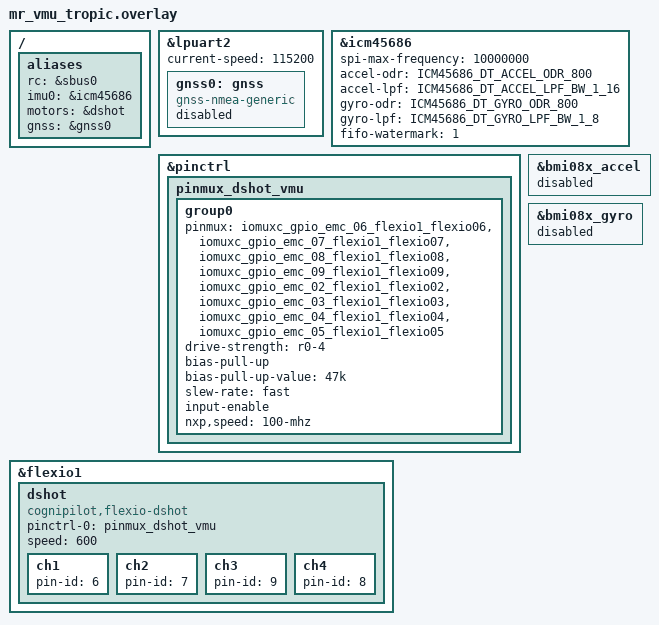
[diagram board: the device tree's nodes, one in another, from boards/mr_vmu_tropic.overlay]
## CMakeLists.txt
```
cmake_minimum_required(VERSION 3.20.0)

list(APPEND DTS_ROOT ${CMAKE_CURRENT_SOURCE_DIR})

get_filename_component(REPO_ROOT ${CMAKE_CURRENT_SOURCE_DIR} DIRECTORY)
get_filename_component(WORKSPACE_ROOT ${REPO_ROOT} DIRECTORY)
set(ZEPHYR_MODULES
  ${WORKSPACE_ROOT}/modules/hal/cmsis
  ${WORKSPACE_ROOT}/modules/hal/cmsis_6
  ${WORKSPACE_ROOT}/modules/hal/nxp
  ${WORKSPACE_ROOT}/modules/lib/cmsis-dsp
  ${WORKSPACE_ROOT}/modules/lib/zephyr_boards
)

find_package(Zephyr REQUIRED HINTS $ENV{ZEPHYR_BASE})
set(CUBS2_TARGET_NAME "cubs2_sil" CACHE STRING "CUBS2 build target/profile name")
project(${CUBS2_TARGET_NAME} LANGUAGES C)

set(CUBS2_FLATBUFFER_SCHEMA_DIR
  ${CMAKE_CURRENT_SOURCE_DIR}/src
)
set(CUBS2_FLATBUFFER_SCHEMA
  ${CUBS2_FLATBUFFER_SCHEMA_DIR}/synapse_topics.fbs
)
set(CUBS2_FLATBUFFER_MOCAP_SCHEMA
  ${CUBS2_FLATBUFFER_SCHEMA_DIR}/synapse_mocap.fbs
)
set(CUBS2_FLATBUFFER_LOG_SCHEMA
  ${CUBS2_FLATBUFFER_SCHEMA_DIR}/synapse_log.fbs
)
set(CUBS2_FLATBUFFER_SIL_SCHEMA
  ${CUBS2_FLATBUFFER_SCHEMA_DIR}/synapse_sil.fbs
)
set(CUBS2_FLATBUFFER_GENERATED_DIR
  ${CMAKE_CURRENT_BINARY_DIR}/generated/flatbuffers
)
set(CUBS2_FLATBUFFER_STAMP
  ${CUBS2_FLATBUFFER_GENERATED_DIR}/.flatcc.stamp
)
set(CUBS2_FLATBUFFER_BFBS_STAMP
  ${CUBS2_FLATBUFFER_GENERATED_DIR}/.bfbs.stamp
)
set(CUBS2_FLATBUFFER_STAGE_STAMP
  ${CUBS2_FLATBUFFER_GENERATED_DIR}/.schema-copy.stamp
)
option(CUBS2_FLATBUFFER_CODEGEN
  "Generate FlatBuffer C headers and binary schemas into the build tree when flatcc is available"
  ON
)

find_program(CUBS2_FLATCC_EXECUTABLE NAMES flatcc)

if(CUBS2_FLATCC_EXECUTABLE)
  get_filename_component(CUBS2_FLATCC_REALPATH ${CUBS2_FLATCC_EXECUTABLE} REALPATH)
  get_filename_component(CUBS2_FLATCC_BIN_DIR ${CUBS2_FLATCC_REALPATH} DIRECTORY)
  get_filename_component(CUBS2_FLATCC_PREFIX ${CUBS2_FLATCC_BIN_DIR} DIRECTORY)
endif()

find_path(CUBS2_FLATCC_INCLUDE_DIR
  NAMES flatcc/flatcc_builder.h
  HINTS ${CUBS2_FLATCC_PREFIX}/include
)

if(NOT EXISTS ${CUBS2_FLATBUFFER_SCHEMA})
  message(FATAL_ERROR
    "Missing FlatBuffer topic schema: ${CUBS2_FLATBUFFER_SCHEMA}. "
    "Run west update to fetch modules/lib/synapse_msgs_fbs."
  )
endif()

if(NOT EXISTS ${CUBS2_FLATBUFFER_MOCAP_SCHEMA})
  message(FATAL_ERROR
    "Missing FlatBuffer mocap schema: ${CUBS2_FLATBUFFER_MOCAP_SCHEMA}. "
    "Run west update to fetch modules/lib/synapse_msgs_fbs."
  )
endif()

if(NOT EXISTS ${CUBS2_FLATBUFFER_LOG_SCHEMA})
  message(FATAL_ERROR
    "Missing FlatBuffer log schema: ${CUBS2_FLATBUFFER_LOG_SCHEMA}. "
    "Run west update to fetch modules/lib/synapse_msgs_fbs."
  )
endif()

if(NOT EXISTS ${CUBS2_FLATBUFFER_SIL_SCHEMA})
  message(FATAL_ERROR
    "Missing FlatBuffer SITL schema: ${CUBS2_FLATBUFFER_SIL_SCHEMA}. "
    "Run west update to fetch modules/lib/synapse_msgs_fbs."
  )
endif()

if(CUBS2_FLATBUFFER_CODEGEN AND CUBS2_FLATCC_EXECUTABLE)
  add_custom_command(
    OUTPUT ${CUBS2_FLATBUFFER_STAGE_STAMP}
    COMMAND ${CMAKE_COMMAND} -E make_directory ${CUBS2_FLATBUFFER_GENERATED_DIR}
    COMMAND ${CMAKE_COMMAND} -E copy_if_different
            ${CUBS2_FLATBUFFER_SCHEMA}
            ${CUBS2_FLATBUFFER_GENERATED_DIR}/synapse_topics.fbs
    COMMAND ${CMAKE_COMMAND} -E copy_if_different
            ${CUBS2_FLATBUFFER_MOCAP_SCHEMA}
            ${CUBS2_FLATBUFFER_GENERATED_DIR}/synapse_mocap.fbs
    COMMAND ${CMAKE_COMMAND} -E copy_if_different
            ${CUBS2_FLATBUFFER_LOG_SCHEMA}
            ${CUBS2_FLATBUFFER_GENERATED_DIR}/synapse_log.fbs
    COMMAND ${CMAKE_COMMAND} -E copy_if_different
            ${CUBS2_FLATBUFFER_SIL_SCHEMA}
            ${CUBS2_FLATBUFFER_GENERATED_DIR}/synapse_sil.fbs
    COMMAND ${CMAKE_COMMAND} -E touch ${CUBS2_FLATBUFFER_STAGE_STAMP}
    DEPENDS
      ${CUBS2_FLATBUFFER_SCHEMA}
      ${CUBS2_FLATBUFFER_MOCAP_SCHEMA}
      ${CUBS2_FLATBUFFER_LOG_SCHEMA}
      ${CUBS2_FLATBUFFER_SIL_SCHEMA}
    COMMENT "Staging FlatBuffer schemas into ${CUBS2_FLATBUFFER_GENERATED_DIR}"
    VERBATIM
  )

  add_custom_command(
    OUTPUT ${CUBS2_FLATBUFFER_STAMP}
    COMMAND ${CUBS2_FLATCC_EXECUTABLE}
            -a
            -I${CUBS2_FLATBUFFER_SCHEMA_DIR}
            -o${CUBS2_FLATBUFFER_GENERATED_DIR}
            ${CUBS2_FLATBUFFER_SCHEMA}
    COMMAND ${CUBS2_FLATCC_EXECUTABLE}
            -a
            -I${CUBS2_FLATBUFFER_SCHEMA_DIR}
            -o${CUBS2_FLATBUFFER_GENERATED_DIR}
            ${CUBS2_FLATBUFFER_MOCAP_SCHEMA}
    COMMAND ${CUBS2_FLATCC_EXECUTABLE}
            -a
            -I${CUBS2_FLATBUFFER_SCHEMA_DIR}
            -o${CUBS2_FLATBUFFER_GENERATED_DIR}
            ${CUBS2_FLATBUFFER_LOG_SCHEMA}
    COMMAND ${CUBS2_FLATCC_EXECUTABLE}
            -a
            -I${CUBS2_FLATBUFFER_SCHEMA_DIR}
            -o${CUBS2_FLATBUFFER_GENERATED_DIR}
            ${CUBS2_FLATBUFFER_SIL_SCHEMA}
    COMMAND ${CMAKE_COMMAND} -E touch ${CUBS2_FLATBUFFER_STAMP}
    DEPENDS
      ${CUBS2_FLATBUFFER_STAGE_STAMP}
      ${CUBS2_FLATBUFFER_SCHEMA}
      ${CUBS2_FLATBUFFER_MOCAP_SCHEMA}
      ${CUBS2_FLATBUFFER_LOG_SCHEMA}
      ${CUBS2_FLATBUFFER_SIL_SCHEMA}
    COMMENT "Generating FlatBuffer headers into ${CUBS2_FLATBUFFER_GENERATED_DIR}"
    VERBATIM
  )

  add_custom_target(cubs2_flatbuffer_codegen DEPENDS ${CUBS2_FLATBUFFER_STAMP})
  add_custom_command(
    OUTPUT ${CUBS2_FLATBUFFER_BFBS_STAMP}
    COMMAND ${CUBS2_FLATCC_EXECUTABLE}
            --schema
            -I${CUBS2_FLATBUFFER_SCHEMA_DIR}
            -o${CUBS2_FLATBUFFER_GENERATED_DIR}
            ${CUBS2_FLATBUFFER_SCHEMA}
    COMMAND ${CUBS2_FLATCC_EXECUTABLE}
            --schema
            -I${CUBS2_FLATBUFFER_SCHEMA_DIR}
            -o${CUBS2_FLATBUFFER_GENERATED_DIR}
            ${CUBS2_FLATBUFFER_MOCAP_SCHEMA}
    COMMAND ${CUBS2_FLATCC_EXECUTABLE}
            --schema
            -I${CUBS2_FLATBUFFER_SCHEMA_DIR}
            -o${CUBS2_FLATBUFFER_GENERATED_DIR}
            ${CUBS2_FLATBUFFER_LOG_SCHEMA}
    COMMAND ${CUBS2_FLATCC_EXECUTABLE}
            --schema
            -I${CUBS2_FLATBUFFER_SCHEMA_DIR}
            -o${CUBS2_FLATBUFFER_GENERATED_DIR}
            ${CUBS2_FLATBUFFER_SIL_SCHEMA}
    COMMAND ${CMAKE_COMMAND} -E touch ${CUBS2_FLATBUFFER_BFBS_STAMP}
    DEPENDS
      ${CUBS2_FLATBUFFER_STAGE_STAMP}
      ${CUBS2_FLATBUFFER_SCHEMA}
      ${CUBS2_FLATBUFFER_MOCAP_SCHEMA}
      ${CUBS2_FLATBUFFER_LOG_SCHEMA}
      ${CUBS2_FLATBUFFER_SIL_SCHEMA}
    COMMENT "Generating FlatBuffer binary schemas into ${CUBS2_FLATBUFFER_GENERATED_DIR}"
    VERBATIM
  )

  add_custom_target(cubs2_flatbuffer_schema_codegen
    DEPENDS ${CUBS2_FLATBUFFER_BFBS_STAMP}
  )
elseif(CUBS2_FLATBUFFER_CODEGEN)
  message(FATAL_ERROR
    "flatcc is required to build CUBS2 because the firmware now compiles "
    "against generated FlatBuffer headers."
  )
endif()

if(NOT CUBS2_FLATCC_INCLUDE_DIR)
  message(FATAL_ERROR
    "Missing flatcc headers. Expected flatcc/flatcc_builder.h near ${CUBS2_FLATCC_EXECUTABLE}."
  )
endif()

if(TARGET cubs2_flatbuffer_codegen)
  add_dependencies(app cubs2_flatbuffer_codegen)
endif()

if(TARGET cubs2_flatbuffer_schema_codegen)
  add_dependencies(app cubs2_flatbuffer_schema_codegen)
endif()

target_include_directories(app PRIVATE
  include
  ${CUBS2_FLATBUFFER_GENERATED_DIR}
  ${CUBS2_FLATCC_INCLUDE_DIR}
  ${ZEPHYR_BASE}/../modules/hal/nxp/mcux/mcux-sdk-ng/drivers/flexio
)

add_subdirectory(src)
add_subdirectory(subsys)
add_subdirectory(drivers)
```

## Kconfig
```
source "Kconfig.zephyr"

menu "CUBS2"

choice CUBS2_SERIAL_BRIDGE_OUTPUT_PROTOCOL
	prompt "Serial bridge RC output protocol"
	default CUBS2_SERIAL_BRIDGE_INTERNAL
	help
	  Select the wire format used when publishing controller RC output over
	  the serial bridge.

config CUBS2_SERIAL_BRIDGE_INTERNAL
	bool "Internal CUBS2 bridge frame"
	help
	  Send 0x55 0xAA framed RcChannels16 payloads. This is the historical
	  SIL/bridge protocol and is not consumed by the PPM Arduino encoder.

config CUBS2_SERIAL_BRIDGE_PPM_ARDUINO
	bool "Arduino PPM encoder frame"
	help
	  Send the 14-byte packet consumed by the wsribunma/ppm_bridge Arduino:
	  0xFF 0xFF, five little-endian uint16 PWM channels, and a little-endian
	  uint16 sum checksum.

endchoice

config CUBS2_PPM_MANUAL_OVERRIDE
	bool "Select manual or autonomous PPM output from incoming RC switch"
	default y if CUBS2_SERIAL_BRIDGE_PPM_ARDUINO
	help
	  Mirror the legacy ROS ppm_bridge behavior: keep both the incoming
	  manual RC channels and the generated autonomous channels, then send
	  manual channels when the mode switch is low and autonomous channels
	  when the mode switch is high. If the manual channels or switch do not
	  look like valid PWM values, the controller stays on autonomous output.

config CUBS2_PPM_AUTO_SWITCH_CHANNEL
	int "Incoming RC channel index used for manual/autonomous switch"
	depends on CUBS2_PPM_MANUAL_OVERRIDE
	default 5
	range 0 15
	help
	  Zero-based RcChannels16 index used as the source mode switch. The
	  legacy Taranis path used joy axes[5], so channel index 5 is the
	  default equivalent.

config CUBS2_PPM_AUTO_SWITCH_THRESHOLD_US
	int "Manual/autonomous switch PWM threshold"
	depends on CUBS2_PPM_MANUAL_OVERRIDE
	default 1500
	range 1000 2000
	help
	  Switch values above this threshold select autonomous output. Values at
	  or below this threshold select manual passthrough.

config CUBS2_SERIAL_BRIDGE_CSYN_OUTPUT
	bool "Route controller output through csyn instead of serial"
	depends on CUBS2_CSYN
	default y
	help
	  Treat synapse/control_output as the Arduino-facing controller output.
	  When enabled, the legacy serial bridge send path does not write the
	  selected RC output to UART or a host serial device.

config CUBS2_SERIAL_BRIDGE_QUIET
	bool "Suppress serial bridge runtime logs"
	default y if CUBS2_SERIAL_BRIDGE_CSYN_OUTPUT
	help
	  Suppress Arduino/serial bridge runtime logs. This keeps native_sim
	  control deployments focused on csyn and controller logs while leaving
	  the legacy serial bridge code available when explicitly enabled.

config CUBS2_FWDBG_LOG
	bool "Print fixed-wing controller debug trace"
	default n
	help
	  Print the periodic FWDBG controller trace from the main control loop.
	  Enable this only when tuning or collecting controller diagnostics.

config CUBS2_HOST_DEPLOY_IO
	bool "Enable native host deploy input state"
	depends on BOARD_NATIVE_SIM
	help
	  Enable native_sim deploy input state fed by csyn topics such as
	  synapse/manual_control and synapse/mocap/frame. The selected
	  controller output is then published on synapse/control_output for an
	  external actuator or Arduino PPM node.

config CUBS2_HOST_DEPLOY_JOYSTICK
	bool "Read manual RC from Linux joystick device in zephyr.exe"
	depends on CUBS2_HOST_DEPLOY_IO
	default y
	help
	  Start a background thread inside zephyr.exe that reads /dev/input/js*
	  events and maps them into RcChannels16 for manual override selection.
	  Deployment normally leaves this disabled and feeds manual_control from
	  an external joystick node over csyn.

config CUBS2_JOYSTICK_DEVICE
	string "Linux joystick device"
	depends on CUBS2_HOST_DEPLOY_JOYSTICK
	default "/dev/input/js0"

config CUBS2_JOYSTICK_AILERON_AXIS
	int "Joystick aileron axis"
	depends on CUBS2_HOST_DEPLOY_JOYSTICK
	default 0

config CUBS2_JOYSTICK_ELEVATOR_AXIS
	int "Joystick elevator axis"
	depends on CUBS2_HOST_DEPLOY_JOYSTICK
	default 1

config CUBS2_JOYSTICK_THROTTLE_AXIS
	int "Joystick throttle axis"
	depends on CUBS2_HOST_DEPLOY_JOYSTICK
	default 2

config CUBS2_JOYSTICK_RUDDER_AXIS
	int "Joystick rudder axis"
	depends on CUBS2_HOST_DEPLOY_JOYSTICK
	default 3

config CUBS2_JOYSTICK_AUTO_BUTTON
	int "Joystick autopilot button"
	depends on CUBS2_HOST_DEPLOY_JOYSTICK
	default 0
	help
	  Button index mapped to RcChannels16 ch5. Released selects manual
	  output; pressed selects autopilot output.

rsource "subsys/Kconfig"
rsource "drivers/Kconfig"

endmenu
```

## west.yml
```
# SPDX-License-Identifier: Apache-2.0

manifest:
  self:
    path: cerebri/cubs2

  remotes:
    - name: zephyrproject-rtos
      url-base: https://github.com/zephyrproject-rtos
    - name: cognipilot
      url-base: https://github.com/CogniPilot

  projects:
    - name: zephyr
      remote: cognipilot
      revision: 2ca24fe101319435b88aa0381e9ff5f78c88a1c3
      path: zephyr
      west-commands: scripts/west-commands.yml
    - name: cmsis
      remote: zephyrproject-rtos
      revision: 512cc7e895e8491696b61f7ba8066b4a182569b8 # loaded in ~/cognipilot/ws/modules/hal/cmsis
      path: modules/hal/cmsis
    - name: cmsis-dsp
      remote: zephyrproject-rtos
      revision: 97512610ec92058f0119450b9e743eeb7e95b5c8 # loaded in ~/cognipilot/ws/modules/lib/cmsis-dsp
      path: modules/lib/cmsis-dsp
    - name: cmsis_6
      remote: zephyrproject-rtos
      revision: 30a859f44ef8ab4dc8f84b03ed586fd16ccf9d74 # loaded in ~/cognipilot/ws/modules/hal/cmsis_6
      path: modules/hal/cmsis_6
    - name: hal_nxp
      remote: cognipilot
      revision: cf8f1631e862528ee044850bcc70273975b90771 # loaded in ~/cognipilot/ws/modules/hal/nxp
      path: modules/hal/nxp
    - name: zephyr_boards
      remote: cognipilot
      revision: eed56ecf0b667552d9d82aa46d1123317f0ef36d
      path: modules/lib/zephyr_boards
    - name: synapse_msgs_fbs
      url: https://github.com/CogniPilot/synapse_msgs_fbs.git
      revision: cerebri2
      path: modules/lib/synapse_msgs_fbs
```

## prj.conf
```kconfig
CONFIG_MAIN_STACK_SIZE=6144
CONFIG_MAIN_THREAD_PRIORITY=2
CONFIG_SYSTEM_WORKQUEUE_STACK_SIZE=2048
CONFIG_THREAD_NAME=y

CONFIG_ASSERT=y
CONFIG_FPU=y

CONFIG_CUBS2_SITL_RX_PORT=4245

CONFIG_LOG=y
CONFIG_LOG_MODE_IMMEDIATE=y
CONFIG_LOG_DEFAULT_LEVEL=2
CONFIG_LOG_CMDS=y
CONFIG_LOG_BACKEND_UART=n
CONFIG_LOG_PRINTK=n

CONFIG_CONSOLE=y
CONFIG_SERIAL=y
CONFIG_UART_ASYNC_API=y
CONFIG_UART_INTERRUPT_DRIVEN=y

CONFIG_SHELL=y
CONFIG_SHELL_BACKEND_SERIAL=y
CONFIG_SHELL_LOG_BACKEND=y
CONFIG_SHELL_PROMPT_UART="cubs2:~$ "
CONFIG_SHELL_STACK_SIZE=4096
CONFIG_DEVICE_SHELL=y
CONFIG_KERNEL_SHELL=y
```

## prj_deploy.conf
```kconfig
# SPDX-License-Identifier: Apache-2.0
#
# CUBS2 deployment profile.
#
# native_sim deployment controller:
#   Zenoh/csyn mocap + manual_control -> controller -> Zenoh/csyn control_output.
# Joystick input and Arduino PPM output are separate Zenoh nodes.

CONFIG_CUBS2_SITL=n
CONFIG_CUBS2_HOST_DEPLOY_IO=y
CONFIG_CUBS2_HOST_DEPLOY_JOYSTICK=n
CONFIG_CUBS2_SERIAL_BRIDGE_INTERNAL=y
CONFIG_CUBS2_SERIAL_BRIDGE_CSYN_OUTPUT=y
CONFIG_CUBS2_PPM_MANUAL_OVERRIDE=y
```

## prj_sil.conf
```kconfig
# SPDX-License-Identifier: Apache-2.0
#
# CUBS2 software-in-the-loop profile.

CONFIG_CUBS2_SITL=y
CONFIG_CUBS2_SERIAL_BRIDGE_INTERNAL=y
```

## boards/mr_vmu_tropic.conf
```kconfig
CONFIG_INPUT=y
CONFIG_INPUT_MODE_SYNCHRONOUS=y
CONFIG_INPUT_SHELL=y
CONFIG_INPUT_EVENT_DUMP=y
CONFIG_INPUT_CRSF=y
CONFIG_INPUT_CRSF_SEND_SYNC=y
CONFIG_INPUT_CRSF_REPORT_FILTER=1
CONFIG_INPUT_CRSF_THREAD_PRIORITY=1
CONFIG_INPUT_CRSF_THREAD_STACK_SIZE=2048
CONFIG_INPUT_CRSF_USE_DTCM_FOR_DMA_BUFFER=y
CONFIG_CODE_DATA_RELOCATION=y

CONFIG_DSP=y
CONFIG_DSP_BACKEND_CMSIS=y
CONFIG_CMSIS_DSP=y

CONFIG_SENSOR=y
CONFIG_SENSOR_ASYNC_API=y
CONFIG_SENSOR_SHELL=y
CONFIG_ICM45686_STREAM=y
CONFIG_PINCTRL=y
CONFIG_CLOCK_CONTROL=y
CONFIG_DMA=y
CONFIG_SPI_NXP_LPSPI_DMA=n
CONFIG_GNSS=y
```

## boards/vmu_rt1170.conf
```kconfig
CONFIG_INPUT=y
CONFIG_INPUT_MODE_SYNCHRONOUS=y
CONFIG_INPUT_SHELL=y
CONFIG_INPUT_EVENT_DUMP=y
CONFIG_INPUT_SBUS=y
CONFIG_INPUT_SBUS_SEND_SYNC=y
CONFIG_INPUT_SBUS_REPORT_FILTER=1
CONFIG_INPUT_SBUS_THREAD_PRIORITY=1
CONFIG_INPUT_SBUS_THREAD_STACK_SIZE=2048

CONFIG_DSP=y
CONFIG_DSP_BACKEND_CMSIS=y
CONFIG_CMSIS_DSP=y

CONFIG_SENSOR=y
CONFIG_SENSOR_SHELL=y
CONFIG_ICM4268X=y
CONFIG_PINCTRL=y
CONFIG_CLOCK_CONTROL=y
CONFIG_DMA=y
CONFIG_SPI_NXP_LPSPI_DMA=n
CONFIG_GNSS=y
```

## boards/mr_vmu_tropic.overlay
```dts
/* SPDX-License-Identifier: Apache-2.0 */

#include <zephyr/dt-bindings/sensor/icm45686.h>

/ {
	aliases {
		rc = &sbus0;
		imu0 = &icm45686;
		motors = &dshot;
		gnss = &gnss0;
	};
};

&lpuart2 {
	status = "okay";
	current-speed = <115200>;

	gnss0: gnss {
		status = "disabled";
		compatible = "gnss-nmea-generic";
	};
};

&icm45686 {
	spi-max-frequency = <10000000>;
	/*
	 * Pace the flight loop directly from the IMU FIFO watermark at 800 Hz.
	 * Keep the filter settings conservative enough to cut motor vibration,
	 * but leave the SPI DMA channels intact so the FIFO read can stay off
	 * the CPU hot path.
	 */
	accel-odr = <ICM45686_DT_ACCEL_ODR_800>;
	accel-lpf = <ICM45686_DT_ACCEL_LPF_BW_1_16>;
	gyro-odr = <ICM45686_DT_GYRO_ODR_800>;
	gyro-lpf = <ICM45686_DT_GYRO_LPF_BW_1_8>;
	fifo-watermark = <1>;
};

&pinctrl {
	pinmux_dshot_vmu: pinmux_dshot_vmu {
		group0 {
			pinmux = <&iomuxc_gpio_emc_06_flexio1_flexio06>,
				 <&iomuxc_gpio_emc_07_flexio1_flexio07>,
				 <&iomuxc_gpio_emc_08_flexio1_flexio08>,
				 <&iomuxc_gpio_emc_09_flexio1_flexio09>,
				 <&iomuxc_gpio_emc_02_flexio1_flexio02>,
				 <&iomuxc_gpio_emc_03_flexio1_flexio03>,
				 <&iomuxc_gpio_emc_04_flexio1_flexio04>,
				 <&iomuxc_gpio_emc_05_flexio1_flexio05>;
			drive-strength = "r0-4";
			bias-pull-up;
			bias-pull-up-value = "47k";
			slew-rate = "fast";
			input-enable;
			nxp,speed = "100-mhz";
		};
	};
};

&flexio1 {
	status = "okay";

	dshot: dshot {
		compatible = "cognipilot,flexio-dshot";
		pinctrl-0 = <&pinmux_dshot_vmu>;
		pinctrl-names = "default";
		status = "okay";
		speed = <600>;

		ch1 {
			pin-id = <6>;
		};

		ch2 {
			pin-id = <7>;
		};

		ch3 {
			pin-id = <9>;
		};

		ch4 {
			pin-id = <8>;
		};
	};
};

&bmi08x_accel {
	status = "disabled";
};

&bmi08x_gyro {
	status = "disabled";
};
```

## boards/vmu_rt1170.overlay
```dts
/* SPDX-License-Identifier: Apache-2.0 */

/ {
	chosen {
		zephyr,console = &lpuart4;
		zephyr,shell-uart = &lpuart4;
		zephyr,uart-mcumgr = &lpuart4;
	};

	aliases {
		rc = &sbus0;
		imu0 = &icm42686_0;
		motors = &dshot;
		gnss = &gnss0;
	};
};

&lpuart2 {
	status = "okay";
	current-speed = <115200>;

	gnss0: gnss {
		status = "disabled";
		compatible = "gnss-nmea-generic";
	};
};

&lpuart6 {
	sbus0: sbus {
		status = "okay";
	};
};

&pinctrl {
	pinmux_dshot_vmu: pinmux_dshot_vmu {
	};
};

&flexio1 {
	status = "okay";

	dshot: dshot {
		compatible = "cognipilot,flexio-dshot";
		pinctrl-0 = <&pinmux_dshot_vmu>;
		pinctrl-names = "default";
		status = "okay";
		speed = <600>;

		ch1 {
			pin-id = <6>;
		};

		ch2 {
			pin-id = <7>;
		};

		ch3 {
			pin-id = <9>;
		};

		ch4 {
			pin-id = <8>;
		};
	};
};
```

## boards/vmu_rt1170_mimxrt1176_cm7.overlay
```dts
#include "vmu_rt1170.overlay"
```

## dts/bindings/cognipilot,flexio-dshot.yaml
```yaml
# Copyright 2024 NXP
# SPDX-License-Identifier: Apache-2.0

description: NXP Flexio DSHOT controller.
  Each flexio timer can be used for generating one dshot pulse.
  The two DSHOT modes supported by flexio are chosen based on the selected polarity -
  Dual 8-bit counters DSHOT mode and Dual 8-bit counters DSHOT Low mode.

compatible: "cognipilot,flexio-dshot"

include: [pinctrl-device.yaml, base.yaml]

properties:
  pinctrl-0:
    required: true

  pinctrl-names:
    required: true

  speed:
    type: int
    default: 600
    description: |
      bitrate of the dshot signal in kbit/s

child-binding:
  description: |
    Flexio DSHOT channel configuration.

  properties:
    pin-id:
      type: int
      required: true
      description: |
        pin-id should be populated with number 'n' specified in the
        FXIO_D<n> data pin of your board's schematic.
    bidirectional-dshot:
      type: boolean
      description: | 
        Enables inverted dshot, where signal level is inverted
        When inverted an DSHOT esc will send back telemetry over 
        the same single wire
```

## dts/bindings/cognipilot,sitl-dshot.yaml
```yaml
# SPDX-License-Identifier: Apache-2.0

description: CUBS2 native_sim DSHOT output device

compatible: "cognipilot,sitl-dshot"

include: sensor-device.yaml

properties:
  channel-count:
    type: int
    required: true
    description: Number of simulated motor output channels.
```

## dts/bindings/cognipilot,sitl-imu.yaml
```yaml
# SPDX-License-Identifier: Apache-2.0

description: CUBS2 native_sim IMU sensor device

compatible: "cognipilot,sitl-imu"

include: sensor-device.yaml
```

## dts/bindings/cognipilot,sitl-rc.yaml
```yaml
# SPDX-License-Identifier: Apache-2.0

description: CUBS2 native_sim RC input device

compatible: "cognipilot,sitl-rc"

include: base.yaml
```

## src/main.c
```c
/*
 * SPDX-License-Identifier: Apache-2.0
 */

#include "control_io.h"
#include "hotpath_memory.h"
#include "topic_shell.h"
#include "serial_bridge.h"
#include "generated_fixed_wing/CubControl_FixedWingOuterLoop.h"

#include <stdbool.h>
#include <stdint.h>
#include <math.h>

#include <zephyr/kernel.h>
#include <zephyr/logging/log.h>

LOG_MODULE_REGISTER(cubs2, LOG_LEVEL_INF);

struct control_context {
	synapse_topic_Vec3f_t gyro;
	synapse_topic_Vec3f_t accel;
	synapse_topic_RcChannels16_t rc;
	synapse_topic_ControlStatus_t status;
	synapse_topic_AttitudeEuler_t attitude;
	synapse_topic_AttitudeEuler_t attitude_desired;
	synapse_topic_RateTriplet_t rate_desired;
	synapse_topic_RateTriplet_t rate_cmd;
	cubs2_mocap_rigid_body_t mocap;
	float dt;
	int64_t now_ms;
};

/* Keep the persistent control-loop working set in DTCM if available. */
static CUBS2_HOTPATH_DTCM_BSS CubControl_FixedWingOuterLoop_t g_model;
static CUBS2_HOTPATH_DTCM_BSS struct control_context g_control_ctx;

static void publish_bridge_state(const struct control_context *ctx)
{
	cubs2_topic_flight_state_publish(&ctx->gyro, &ctx->accel, &ctx->rc, &ctx->status,
					   &ctx->attitude, &ctx->attitude_desired,
					   &ctx->rate_desired, &ctx->rate_cmd);
}

static float clampf_local(float value, float min_value, float max_value)
{
	if (value < min_value) {
		return min_value;
	}
	if (value > max_value) {
		return max_value;
	}
	return value;
}

static int32_t pwm_from_centered_stick(float value, bool inverted)
{
	const float sign = inverted ? -1.0f : 1.0f;
	return (int32_t)(1500.0f + 500.0f * sign * clampf_local(value, -1.0f, 1.0f));
}

static int32_t pwm_from_throttle(float value)
{
	return (int32_t)(1000.0f + 1000.0f * clampf_local(value, 0.0f, 1.0f));
}

static void quat_to_euler(const cubs2_mocap_rigid_body_t *mocap, float *roll, float *pitch,
				  float *yaw)
{
	const float qw = mocap->qw;
	const float qx = mocap->qx;
	const float qy = mocap->qy;
	const float qz = mocap->qz;
	const float sinr_cosp = 2.0f * (qw * qx + qy * qz);
	const float cosr_cosp = 1.0f - 2.0f * (qx * qx + qy * qy);
	const float sinp = 2.0f * (qw * qy - qz * qx);
	const float siny_cosp = 2.0f * (qw * qz + qx * qy);
	const float cosy_cosp = 1.0f - 2.0f * (qy * qy + qz * qz);

	*roll = atan2f(sinr_cosp, cosr_cosp);
	*pitch = asinf(clampf_local(sinp, -1.0f, 1.0f));
	*yaw = atan2f(siny_cosp, cosy_cosp);
}

static void fixed_wing_bridge_map_input(CubControl_FixedWingOuterLoop_t *m, const struct control_context *ctx)
{
	float roll = ctx->accel.x;
	float pitch = ctx->accel.y;
	float yaw = ctx->accel.z;

	if (ctx->mocap.valid) {
		quat_to_euler(&ctx->mocap, &roll, &pitch, &yaw);
		pitch = -pitch;
		m->x = ctx->mocap.x;
		m->y = ctx->mocap.y;
		m->z = ctx->mocap.z;
	} else {
		m->x = ctx->gyro.x;
		m->y = ctx->gyro.y;
		m->z = ctx->gyro.z;
	}

	m->roll = roll;
	m->pitch = pitch;
	m->yaw = yaw;
}

static void fixed_wing_bridge_map_output(const CubControl_FixedWingOuterLoop_t *m, synapse_topic_RcChannels16_t *rc)
{
	rc->ch0 = pwm_from_centered_stick((float)m->aileron, true);
	rc->ch1 = pwm_from_centered_stick((float)m->elevator, true);
	rc->ch2 = pwm_from_throttle((float)m->throttle);
	rc->ch3 = pwm_from_centered_stick((float)m->rudder, false);
	rc->ch4 = (int32_t)clampf_local((float)m->stabilizer, 1000.0f, 2000.0f);
	rc->ch5 = (int32_t)m->current_wp;
	rc->ch6 = (int32_t)(1000.0f * (float)m->des_v);
	rc->ch7 = (int32_t)(1000.0f * (float)m->phi_cmd);
	rc->ch8 = (int32_t)(1000.0f * (float)m->chi_err);
}

static bool fixed_wing_bridge_auto_mode(const synapse_topic_RcChannels16_t *manual_rc,
					const synapse_topic_ControlStatus_t *status)
{
#if defined(CONFIG_CUBS2_PPM_MANUAL_OVERRIDE)
	const int32_t *manual_channels = cubs2_topic_rc_channels_data_const(manual_rc);
	bool manual_valid = status->rc_valid;
	int32_t switch_us = manual_channels[CONFIG_CUBS2_PPM_AUTO_SWITCH_CHANNEL];

	for (size_t i = 0U; i < 5U; i++) {
		manual_valid = manual_valid && (manual_channels[i] >= 900) &&
			       (manual_channels[i] <= 2100);
	}
	manual_valid = manual_valid && (switch_us >= 900) && (switch_us <= 2100);

	return !manual_valid || (switch_us > CONFIG_CUBS2_PPM_AUTO_SWITCH_THRESHOLD_US);
#else
	ARG_UNUSED(manual_rc);
	ARG_UNUSED(status);
	return true;
#endif
}

static bool fixed_wing_bridge_select_ppm_output(
	const synapse_topic_RcChannels16_t *manual_rc, const synapse_topic_RcChannels16_t *auto_rc,
	const synapse_topic_ControlStatus_t *status, bool auto_mode, synapse_topic_RcChannels16_t *out_rc)
{
#if defined(CONFIG_CUBS2_PPM_MANUAL_OVERRIDE)
	const int32_t *manual_channels = cubs2_topic_rc_channels_data_const(manual_rc);
#if !defined(CONFIG_CUBS2_SERIAL_BRIDGE_QUIET)
	static int s_last_auto_mode = -1;
#endif
	bool manual_valid = status->rc_valid;
	int32_t switch_us = manual_channels[CONFIG_CUBS2_PPM_AUTO_SWITCH_CHANNEL];

	for (size_t i = 0U; i < 5U; i++) {
		manual_valid = manual_valid && (manual_channels[i] >= 900) &&
			       (manual_channels[i] <= 2100);
	}
	manual_valid = manual_valid && (switch_us >= 900) && (switch_us <= 2100);

	*out_rc = auto_mode ? *auto_rc : *manual_rc;

#if !defined(CONFIG_CUBS2_SERIAL_BRIDGE_QUIET)
	if ((int)auto_mode != s_last_auto_mode) {
		if (manual_valid) {
			LOG_INF("PPM bridge mode: %s switch_ch%u=%ld",
				auto_mode ? "auto" : "manual",
				(unsigned int)CONFIG_CUBS2_PPM_AUTO_SWITCH_CHANNEL,
				(long)switch_us);
		} else {
			LOG_INF("PPM bridge mode: auto (manual RC unavailable)");
		}
		s_last_auto_mode = (int)auto_mode;
	}
#endif

	return auto_mode;
#else
	ARG_UNUSED(manual_rc);
	ARG_UNUSED(status);
	ARG_UNUSED(auto_mode);
	*out_rc = *auto_rc;
	return true;
#endif
}

int main(void)
{
	struct control_context *const ctx = &g_control_ctx;
	const k_timeout_t controller_timeout =
		K_NSEC(CUBCONTROL_FIXEDWINGOUTERLOOP_PERIOD_NS);
	bool previous_auto_mode = false;
	int rc;

	*ctx = (struct control_context){0};
	CubControl_FixedWingOuterLoop_init(&g_model);
	g_model.dt = CUBCONTROL_FIXEDWINGOUTERLOOP_PERIOD_S;

	rc = cubs2_control_io_init();
	if (rc != 0) {
		return rc;
	}

	rc = cubs2_serial_bridge_init();
	if (rc != 0) {
#if !defined(CONFIG_CUBS2_SERIAL_BRIDGE_QUIET)
		LOG_ERR("Failed to initialize serial bridge: %d", rc);
#endif
	}

	LOG_INF("CUBS2 Fixed-Wing Bridge starting");

	while (true) {
		// Wait for next telemetry packet or generated-period trigger. In SITL this
		// also stages the simulated mocap pose; on flight hardware it
		// leaves ctx->mocap invalid.
		cubs2_control_input_wait(&ctx->gyro, &ctx->accel, &ctx->rc, &ctx->status,
					 CUBCONTROL_FIXEDWINGOUTERLOOP_PERIOD_S,
					 controller_timeout, &ctx->dt, &ctx->mocap);
		ctx->now_ms = k_uptime_get();
		synapse_topic_RcChannels16_t manual_rc = ctx->rc;
		synapse_topic_RcChannels16_t auto_rc = {0};
		bool auto_mode = fixed_wing_bridge_auto_mode(&manual_rc, &ctx->status);

		// Fall back to the serial bridge mocap source when no other source
		// has provided a valid pose this cycle.
		if (!ctx->mocap.valid) {
			cubs2_serial_bridge_get_mocap(&ctx->mocap);
		}

		if (auto_mode && !previous_auto_mode) {
			CubControl_FixedWingOuterLoop_init(&g_model);
			g_model.dt = CUBCONTROL_FIXEDWINGOUTERLOOP_PERIOD_S;
		}
		previous_auto_mode = auto_mode;

		// Update model inputs
		fixed_wing_bridge_map_input(&g_model, ctx);

		// Advance one generated-period discrete control step.
		CubControl_FixedWingOuterLoop_step(&g_model);

		// Map model outputs to autonomous RC sticks, then mirror the legacy
		// ROS ppm_bridge manual/autonomous switch behavior.
		fixed_wing_bridge_map_output(&g_model, &auto_rc);
		(void)fixed_wing_bridge_select_ppm_output(&manual_rc, &auto_rc, &ctx->status, auto_mode,
							  &ctx->rc);

#if defined(CONFIG_CUBS2_FWDBG_LOG)
		LOG_INF("FWDBG,%.3f,%.3f,%.3f,%.3f,%.3f,%.3f,%.3f,%.3f,%.3f,%.3f,%.3f,%.3f,%.3f,%.3f,%.3f,%.3f,%d,%d,%.3f,%.3f",
			(double)g_model.time_s,
			(double)g_model.x, (double)g_model.y,
			(double)g_model.z, (double)g_model.roll,
			(double)g_model.pitch, (double)g_model.yaw,
			(double)g_model.aileron, (double)g_model.elevator,
			(double)g_model.throttle, (double)g_model.rudder,
			(double)g_model.stabilizer, (double)g_model.des_heading,
			(double)g_model.vx_est, (double)g_model.vy_est,
			(double)g_model.phi_cmd, (double)g_model.chi_err,
			(int)g_model.current_wp, (int)g_model.airborne,
			(double)g_model.des_v, (double)g_model.des_gamma);
#endif

		// Publish stick overrides to the bridge output
		publish_bridge_state(ctx);
		cubs2_topic_rc_published();

		// Send RC overrides back to Ubuntu bridge
		cubs2_serial_bridge_send_rc(&ctx->rc);
	}

	return 0;
}
```

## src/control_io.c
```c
/*
 * SPDX-License-Identifier: Apache-2.0
 */

#include "control_io.h"

#include <errno.h>

#include <zephyr/kernel.h>
#include <zephyr/logging/log.h>

#if defined(CONFIG_CUBS2_SITL)
#include "sitl_flatbuffer.h"
#include "sitl_udp_coordinator.h"
#endif

#if defined(CONFIG_CUBS2_HOST_DEPLOY_IO)
#include "host_deploy_io.h"
#endif

LOG_MODULE_DECLARE(cubs2, LOG_LEVEL_INF);

K_SEM_DEFINE(g_input_sem, 0, 1);

int cubs2_control_io_init(void)
{
#if defined(CONFIG_CUBS2_HOST_DEPLOY_IO)
	return cubs2_host_deploy_io_init();
#else
	return 0;
#endif
}

void cubs2_control_input_trigger(void)
{
	k_sem_give(&g_input_sem);
}

void cubs2_control_input_wait(synapse_topic_Vec3f_t *gyro,
				synapse_topic_Vec3f_t *accel,
				synapse_topic_RcChannels16_t *rc,
				synapse_topic_ControlStatus_t *status,
				float controller_period_s,
				k_timeout_t controller_timeout,
				float *dt,
				cubs2_mocap_rigid_body_t *mocap)
{
	uint8_t rc_link_quality = 0U;
	bool rc_valid = false;
	bool imu_valid = false;

#if !defined(CONFIG_CUBS2_SITL)
	// Flight: wait for the next input trigger or one generated controller period.
	(void)k_sem_take(&g_input_sem, controller_timeout);
#endif

	// Default values if no real sensor data is present
	*dt = controller_period_s;
	status->imu_ok = true;
	status->rc_valid = true;

	// Default: no mocap from this source (flight build gets it from the
	// serial bridge instead).
	if (mocap != NULL) {
		*mocap = (cubs2_mocap_rigid_body_t){0};
	}

#if defined(CONFIG_CUBS2_SITL)
	uint8_t buf[CUBS2_SITL_INPUT_MAX_SIZE];
	size_t len = 0U;
	uint32_t generation = 0U;
	static uint32_t s_last_generation;   // last plant step we consumed
	bool have_input = false;

	// Lockstep: block until the plant publishes a NEW input (its generation
	// counter bumps). The controller dt still comes from the generated
	// Modelica period passed above; the plant/bridge decides packet cadence. Two
	// guards keep it from deadlocking:
	//   * before any pose has arrived (generation == 0) proceed immediately, so
	//     the controller emits a first packet to prime the (also-waiting) plant;
	//   * a 1 s ceiling keeps a dead/paused peer from hanging the loop forever.
	static bool s_primed;   // emitted the initial control to prime the plant?
	const int64_t deadline = k_uptime_get() + 1000;
	while (true) {
		uint32_t gen;
		size_t l;

		if (cubs2_sitl_udp_latest_input_get(buf, sizeof(buf), &l, &gen)) {
			if (gen != s_last_generation) {
				s_last_generation = gen;
				len = l;
				have_input = true;
				s_primed = true;
				break;   // fresh plant step -> consume it
			}
		} else if (!s_primed) {
			s_primed = true;
			break;   // no pose has ever arrived -> emit one control to prime
		}
		if (k_uptime_get() >= deadline) {
			break;   // safety: peer stalled
		}
		// Yield so the SITL rx thread can drain the plant's reply. (This also
		// replaces the yield the old k_sem_take used to provide.)
		k_sleep(K_MSEC(1));
	}
	(void)generation;

	if (have_input &&
	    cubs2_sitl_fb_unpack_input(buf, len, gyro, accel, rc, &rc_link_quality, &rc_valid,
				       &imu_valid, mocap)) {
		status->rc_link_quality = rc_link_quality;
		status->rc_valid = rc_valid;
		status->imu_ok = imu_valid;
	}
#else
	ARG_UNUSED(rc_link_quality);
	ARG_UNUSED(rc_valid);
	ARG_UNUSED(imu_valid);
#endif

#if defined(CONFIG_CUBS2_HOST_DEPLOY_IO)
	if (mocap != NULL) {
		(void)cubs2_host_deploy_io_get_mocap(mocap);
	}
	if (cubs2_host_deploy_io_get_rc(rc)) {
		status->rc_valid = true;
		status->rc_link_quality = 100U;
	} else {
		status->rc_valid = false;
		status->rc_link_quality = 0U;
	}
#endif
}
```

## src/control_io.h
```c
#ifndef CUBS2_CONTROL_IO_H_
#define CUBS2_CONTROL_IO_H_

#include "topic_flatbuffer.h"

#include <zephyr/kernel.h>

int cubs2_control_io_init(void);
void cubs2_control_input_wait(synapse_topic_Vec3f_t *gyro,
				synapse_topic_Vec3f_t *accel,
				synapse_topic_RcChannels16_t *rc,
				synapse_topic_ControlStatus_t *status,
				float controller_period_s,
				k_timeout_t controller_timeout,
				float *dt,
				cubs2_mocap_rigid_body_t *mocap);

void cubs2_control_input_trigger(void);

#endif
```

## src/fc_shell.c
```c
/*
 * SPDX-License-Identifier: Apache-2.0
 */

#include "topic_shell.h"
#include "flight_mode.h"

#include <zephyr/kernel.h>
#include <zephyr/shell/shell.h>

static void fc_latest_state(synapse_topic_Vec3f_t *gyro, synapse_topic_Vec3f_t *accel,
			    synapse_topic_RcChannels16_t *rc,
			    synapse_topic_ControlStatus_t *status,
			    synapse_topic_AttitudeEuler_t *attitude,
			    synapse_topic_AttitudeEuler_t *attitude_desired,
			    synapse_topic_RateTriplet_t *rate_desired,
			    synapse_topic_RateTriplet_t *rate_cmd)
{
	(void)cubs2_topic_flight_state_get(gyro, accel, rc, status, attitude,
					     attitude_desired, rate_desired, rate_cmd);
}

static int cmd_fc_status(const struct shell *sh, size_t argc, char **argv)
{
	synapse_topic_Vec3f_t gyro = {0};
	synapse_topic_Vec3f_t accel = {0};
	synapse_topic_RcChannels16_t rc = {0};
	synapse_topic_ControlStatus_t status = {0};
	synapse_topic_AttitudeEuler_t attitude = {0};
	synapse_topic_AttitudeEuler_t attitude_desired = {0};
	synapse_topic_RateTriplet_t rate_desired = {0};
	synapse_topic_RateTriplet_t rate_cmd = {0};
	int64_t now_ms = k_uptime_get();
	int64_t rc_age_ms;

	ARG_UNUSED(argc);
	ARG_UNUSED(argv);

	fc_latest_state(&gyro, &accel, &rc, &status, &attitude, &attitude_desired,
			&rate_desired, &rate_cmd);
	rc_age_ms = status.rc_valid ? (now_ms - status.rc_stamp_ms) : -1;

	shell_print(sh,
		    "mode=%s armed=%d imu_ok=%d rc_valid=%d rc_stale=%d arm_switch=%d rc_age_ms=%lld lq=%u throttle_us=%ld",
		    cubs2_flight_mode_name((enum cubs2_flight_mode)status.flight_mode),
		    status.armed ? 1 : 0,
		    status.imu_ok ? 1 : 0,
		    status.rc_valid ? 1 : 0,
		    status.rc_stale ? 1 : 0,
		    status.arm_switch ? 1 : 0,
		    (long long)rc_age_ms,
		    (unsigned int)status.rc_link_quality,
		    (long)status.throttle_us);
	shell_print(sh,
		    "rate_desired roll=%0.3f pitch=%0.3f yaw=%0.3f rate_cmd roll=%0.3f pitch=%0.3f yaw=%0.3f",
		    (double)rate_desired.roll,
		    (double)rate_desired.pitch,
		    (double)rate_desired.yaw,
		    (double)rate_cmd.roll,
		    (double)rate_cmd.pitch,
		    (double)rate_cmd.yaw);
	shell_print(sh,
		    "attitude roll=%0.3f pitch=%0.3f yaw=%0.3f attitude_desired roll=%0.3f pitch=%0.3f yaw=%0.3f",
		    (double)attitude.roll,
		    (double)attitude.pitch,
		    (double)attitude.yaw,
		    (double)attitude_desired.roll,
		    (double)attitude_desired.pitch,
		    (double)attitude_desired.yaw);

	return 0;
}

static int cmd_fc_gyro(const struct shell *sh, size_t argc, char **argv)
{
	synapse_topic_Vec3f_t gyro = {0};
	synapse_topic_Vec3f_t accel = {0};
	synapse_topic_RcChannels16_t rc = {0};
	synapse_topic_ControlStatus_t status = {0};
	synapse_topic_AttitudeEuler_t attitude = {0};
	synapse_topic_AttitudeEuler_t attitude_desired = {0};
	synapse_topic_RateTriplet_t rate_desired = {0};
	synapse_topic_RateTriplet_t rate_cmd = {0};

	ARG_UNUSED(argc);
	ARG_UNUSED(argv);

	fc_latest_state(&gyro, &accel, &rc, &status, &attitude, &attitude_desired,
			&rate_desired, &rate_cmd);

	shell_print(sh,
		    "gyro_rad_s x=%0.5f y=%0.5f z=%0.5f",
		    (double)gyro.x,
		    (double)gyro.y,
		    (double)gyro.z);
	shell_print(sh,
		    "accel_m_s2 x=%0.5f y=%0.5f z=%0.5f",
		    (double)accel.x,
		    (double)accel.y,
		    (double)accel.z);

	return 0;
}

static int cmd_fc_rc(const struct shell *sh, size_t argc, char **argv)
{
	synapse_topic_Vec3f_t gyro = {0};
	synapse_topic_Vec3f_t accel = {0};
	synapse_topic_RcChannels16_t rc = {0};
	synapse_topic_ControlStatus_t status = {0};
	synapse_topic_AttitudeEuler_t attitude = {0};
	synapse_topic_AttitudeEuler_t attitude_desired = {0};
	synapse_topic_RateTriplet_t rate_desired = {0};
	synapse_topic_RateTriplet_t rate_cmd = {0};

	ARG_UNUSED(argc);
	ARG_UNUSED(argv);

	fc_latest_state(&gyro, &accel, &rc, &status, &attitude, &attitude_desired,
			&rate_desired, &rate_cmd);

	shell_print(sh,
		    "rc us ch0=%ld ch1=%ld ch2=%ld ch3=%ld ch4=%ld ch5=%ld ch6=%ld ch7=%ld",
		    (long)rc.ch0,
		    (long)rc.ch1,
		    (long)rc.ch2,
		    (long)rc.ch3,
		    (long)rc.ch4,
		    (long)rc.ch5,
		    (long)rc.ch6,
		    (long)rc.ch7);

	return 0;
}

SHELL_STATIC_SUBCMD_SET_CREATE(
	sub_fc,
	SHELL_CMD(status, NULL, "show latest flight-control state", cmd_fc_status),
	SHELL_CMD(gyro, NULL, "show latest gyro and accel sample", cmd_fc_gyro),
	SHELL_CMD(rc, NULL, "show latest RC channel sample", cmd_fc_rc),
	SHELL_SUBCMD_SET_END);
SHELL_CMD_REGISTER(fc, &sub_fc, "flight-control debug commands", NULL);
```

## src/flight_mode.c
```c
/*
 * SPDX-License-Identifier: Apache-2.0
 */

#include "flight_mode.h"

enum cubs2_flight_mode cubs2_flight_mode_from_rc(
	const synapse_topic_RcChannels16_t *rc)
{
	const int32_t *channels;

	if (rc == NULL) {
		return CUBS2_FLIGHT_MODE_ACRO;
	}

	channels = cubs2_topic_rc_channels_data_const(rc);
	if (channels[CUBS2_FLIGHT_MODE_CHANNEL_INDEX] >= CUBS2_FLIGHT_MODE_SWITCH_US) {
		return CUBS2_FLIGHT_MODE_AUTO_LEVEL;
	}

	return CUBS2_FLIGHT_MODE_ACRO;
}

const char *cubs2_flight_mode_name(enum cubs2_flight_mode mode)
{
	switch (mode) {
	case CUBS2_FLIGHT_MODE_ACRO:
		return "ACRO";
	case CUBS2_FLIGHT_MODE_AUTO_LEVEL:
		return "AUTO_LEVEL";
	default:
		return "UNKNOWN";
	}
}
```

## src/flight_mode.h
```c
/*
 * SPDX-License-Identifier: Apache-2.0
 */

#ifndef CUBS2_FLIGHT_MODE_H_
#define CUBS2_FLIGHT_MODE_H_

enum cubs2_flight_mode {
	CUBS2_FLIGHT_MODE_UNKNOWN = 0,
	CUBS2_FLIGHT_MODE_ACRO = 1,
	CUBS2_FLIGHT_MODE_AUTO_LEVEL = 2,
};

#endif /* CUBS2_FLIGHT_MODE_H_ */
```

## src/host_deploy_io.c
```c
/*
 * SPDX-License-Identifier: Apache-2.0
 */

#include "host_deploy_io.h"
#include "control_io.h"

#include <errno.h>
#include <string.h>

#include <zephyr/kernel.h>
#include <zephyr/logging/log.h>

#if defined(CONFIG_CUBS2_HOST_DEPLOY_JOYSTICK)
#include <fcntl.h>
#include <linux/joystick.h>
#include <unistd.h>
#endif

LOG_MODULE_REGISTER(cubs2_host_deploy_io, LOG_LEVEL_INF);

#define HOST_DEPLOY_JOYSTICK_STACK_SIZE 2048
#define HOST_DEPLOY_JOYSTICK_PRIORITY 5

static struct k_mutex g_input_mutex;
static cubs2_mocap_rigid_body_t g_latest_mocap;
static synapse_topic_RcChannels16_t g_latest_rc;
static bool g_have_mocap;
static bool g_have_rc;

#if defined(CONFIG_CUBS2_HOST_DEPLOY_JOYSTICK)
K_THREAD_STACK_DEFINE(g_joystick_stack, HOST_DEPLOY_JOYSTICK_STACK_SIZE);
static struct k_thread g_joystick_thread;
#endif

void cubs2_host_deploy_io_put_rc(const synapse_topic_RcChannels16_t *rc, bool valid)
{
	if (rc == NULL) {
		return;
	}

	k_mutex_lock(&g_input_mutex, K_FOREVER);
	g_latest_rc = *rc;
	g_have_rc = valid;
	k_mutex_unlock(&g_input_mutex);

	if (valid) {
		cubs2_control_input_trigger();
	}
}

void cubs2_host_deploy_io_put_mocap_payload(const uint8_t *buf, size_t len)
{
	cubs2_mocap_rigid_body_t mocap;
	const float mocap_mm_to_m = 0.001f;

	if (buf == NULL || !cubs2_topic_fb_unpack_mocap_frame(buf, len, &mocap)) {
		return;
	}

	mocap.x *= mocap_mm_to_m;
	mocap.y *= mocap_mm_to_m;
	mocap.z *= mocap_mm_to_m;

	k_mutex_lock(&g_input_mutex, K_FOREVER);
	g_latest_mocap = mocap;
	g_have_mocap = mocap.valid;
	k_mutex_unlock(&g_input_mutex);

	cubs2_control_input_trigger();
}

bool cubs2_host_deploy_io_get_mocap(cubs2_mocap_rigid_body_t *mocap)
{
	bool have_mocap;

	if (mocap == NULL) {
		return false;
	}

	k_mutex_lock(&g_input_mutex, K_FOREVER);
	*mocap = g_latest_mocap;
	have_mocap = g_have_mocap;
	k_mutex_unlock(&g_input_mutex);

	return have_mocap;
}

bool cubs2_host_deploy_io_get_rc(synapse_topic_RcChannels16_t *rc)
{
	bool have_rc;

	if (rc == NULL) {
		return false;
	}

	k_mutex_lock(&g_input_mutex, K_FOREVER);
	*rc = g_latest_rc;
	have_rc = g_have_rc;
	k_mutex_unlock(&g_input_mutex);

	return have_rc;
}

#if defined(CONFIG_CUBS2_HOST_DEPLOY_JOYSTICK)
static void host_deploy_store_rc(const synapse_topic_RcChannels16_t *rc)
{
	k_mutex_lock(&g_input_mutex, K_FOREVER);
	g_latest_rc = *rc;
	g_have_rc = true;
	k_mutex_unlock(&g_input_mutex);
}

static int32_t joystick_axis_to_pwm(int16_t value, bool inverted)
{
	int32_t centered = 1500;
	int32_t scaled = ((int32_t)value * 500) / 32767;

	if (inverted) {
		scaled = -scaled;
	}

	return centered + scaled;
}

static int32_t joystick_throttle_to_pwm(int16_t value)
{
	/* Linux joystick axes are usually -32767..32767. Map high stick to 2000. */
	return 1000 + (((int32_t)(32767 - value) * 1000) / 65534);
}

static void joystick_apply_axis(synapse_topic_RcChannels16_t *rc, uint8_t axis, int16_t value)
{
	switch (axis) {
	case CONFIG_CUBS2_JOYSTICK_AILERON_AXIS:
		rc->ch0 = joystick_axis_to_pwm(value, false);
		break;
	case CONFIG_CUBS2_JOYSTICK_ELEVATOR_AXIS:
		rc->ch1 = joystick_axis_to_pwm(value, true);
		break;
	case CONFIG_CUBS2_JOYSTICK_THROTTLE_AXIS:
		rc->ch2 = joystick_throttle_to_pwm(value);
		break;
	case CONFIG_CUBS2_JOYSTICK_RUDDER_AXIS:
		rc->ch3 = joystick_axis_to_pwm(value, false);
		break;
	default:
		break;
	}
}

static void joystick_apply_button(synapse_topic_RcChannels16_t *rc, uint8_t button, int16_t value)
{
	if (button == CONFIG_CUBS2_JOYSTICK_AUTO_BUTTON) {
		rc->ch5 = value ? 2000 : 1000;
	}
}

static void joystick_thread(void *p1, void *p2, void *p3)
{
	ARG_UNUSED(p1);
	ARG_UNUSED(p2);
	ARG_UNUSED(p3);

	while (true) {
		const char *device = CONFIG_CUBS2_JOYSTICK_DEVICE;
		int fd = open(device, O_RDONLY);

		if (fd < 0) {
			LOG_WRN("joystick open failed for %s: %d", device, errno);
			k_sleep(K_SECONDS(1));
			continue;
		}

		LOG_INF("joystick opened on %s", device);

		synapse_topic_RcChannels16_t rc = {
			.ch0 = 1500,
			.ch1 = 1500,
			.ch2 = 1000,
			.ch3 = 1500,
			.ch4 = 1900,
			.ch5 = 1000,
		};

		host_deploy_store_rc(&rc);

		while (true) {
			struct js_event event;
			ssize_t n = read(fd, &event, sizeof(event));

			if (n != sizeof(event)) {
				LOG_WRN("joystick read failed for %s: %d", device, errno);
				break;
			}

			event.type &= ~JS_EVENT_INIT;
			if (event.type == JS_EVENT_AXIS) {
				joystick_apply_axis(&rc, event.number, event.value);
				host_deploy_store_rc(&rc);
			} else if (event.type == JS_EVENT_BUTTON) {
				joystick_apply_button(&rc, event.number, event.value);
				host_deploy_store_rc(&rc);
			}
		}

		close(fd);
		k_sleep(K_MSEC(250));
	}
}
#endif

int cubs2_host_deploy_io_init(void)
{
	int rc = 0;

	k_mutex_init(&g_input_mutex);

#if defined(CONFIG_CUBS2_HOST_DEPLOY_JOYSTICK)
	k_thread_create(&g_joystick_thread, g_joystick_stack,
			K_THREAD_STACK_SIZEOF(g_joystick_stack), joystick_thread,
			NULL, NULL, NULL, HOST_DEPLOY_JOYSTICK_PRIORITY, 0, K_NO_WAIT);
	k_thread_name_set(&g_joystick_thread, "cubs2_joystick");
#endif

	return rc;
}
```

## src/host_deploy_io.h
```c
#ifndef CUBS2_HOST_DEPLOY_IO_H_
#define CUBS2_HOST_DEPLOY_IO_H_

#include <stdbool.h>
#include <stddef.h>
#include <stdint.h>

#include "topic_flatbuffer.h"

int cubs2_host_deploy_io_init(void);

bool cubs2_host_deploy_io_get_mocap(cubs2_mocap_rigid_body_t *mocap);

bool cubs2_host_deploy_io_get_rc(synapse_topic_RcChannels16_t *rc);

void cubs2_host_deploy_io_put_mocap_payload(const uint8_t *buf, size_t len);

void cubs2_host_deploy_io_put_rc(const synapse_topic_RcChannels16_t *rc, bool valid);

#endif /* CUBS2_HOST_DEPLOY_IO_H_ */
```

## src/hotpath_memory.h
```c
#ifndef CUBS2_HOTPATH_MEMORY_H_
#define CUBS2_HOTPATH_MEMORY_H_

#include <zephyr/devicetree.h>

#if defined(CONFIG_BOARD_MR_VMU_TROPIC_MIMXRT1064) && DT_HAS_CHOSEN(zephyr_dtcm) && \
	DT_NODE_HAS_STATUS_OKAY(DT_CHOSEN(zephyr_dtcm))
#include <zephyr/linker/section_tags.h>
#define CUBS2_HOTPATH_DTCM_BSS __dtcm_bss_section
#else
#define CUBS2_HOTPATH_DTCM_BSS
#endif

#endif
```

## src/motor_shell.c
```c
/*
 * SPDX-License-Identifier: Apache-2.0
 */

#include "motor_output.h"

#include "topic_shell.h"

#include <errno.h>
#include <stdlib.h>

#include <zephyr/drivers/misc/nxp_flexio_dshot/nxp_flexio_dshot.h>
#include <zephyr/shell/shell.h>

static int cmd_motor_status(const struct shell *sh, size_t argc, char **argv)
{
	synapse_topic_MotorValues4f_t test_motors = {0};
	synapse_topic_MotorRaw4u16_t test_raw = {0};
	synapse_topic_MotorValues4f_t motors = {0};
	synapse_topic_MotorRaw4u16_t raw = {0};
	bool active;
	bool raw_active;
	bool armed;
	bool test_mode;

	ARG_UNUSED(argc);
	ARG_UNUSED(argv);

	active = cubs2_motor_test_get(&test_motors);
	raw_active = cubs2_motor_raw_test_get(&test_raw);
	(void)cubs2_topic_motor_output_get(&motors, &raw, &armed, &test_mode);
	shell_print(sh,
		    "motor_test=%d test_m0=%0.3f test_m1=%0.3f test_m2=%0.3f test_m3=%0.3f",
		    active ? 1 : 0,
		    (double)test_motors.m0,
		    (double)test_motors.m1,
		    (double)test_motors.m2,
		    (double)test_motors.m3);
	shell_print(sh,
		    "raw_test=%d raw_m0=%u raw_m1=%u raw_m2=%u raw_m3=%u",
		    raw_active ? 1 : 0,
		    (unsigned int)test_raw.m0,
		    (unsigned int)test_raw.m1,
		    (unsigned int)test_raw.m2,
		    (unsigned int)test_raw.m3);
	shell_print(sh,
		    "last_out armed=%d test_mode=%d m0=%0.3f/%u m1=%0.3f/%u m2=%0.3f/%u m3=%0.3f/%u",
		    armed ? 1 : 0,
		    test_mode ? 1 : 0,
		    (double)motors.m0, (unsigned int)raw.m0,
		    (double)motors.m1, (unsigned int)raw.m1,
		    (double)motors.m2, (unsigned int)raw.m2,
		    (double)motors.m3, (unsigned int)raw.m3);
	shell_print(sh, "guess: m0=front-right m1=rear-right m2=rear-left m3=front-left");

	return 0;
}

static int cmd_motor_stop(const struct shell *sh, size_t argc, char **argv)
{
	ARG_UNUSED(argc);
	ARG_UNUSED(argv);

	cubs2_motor_test_clear();
	cubs2_motor_raw_test_clear();
	if (cubs2_motor_output_ready()) {
		cubs2_motor_output_write_all(&(synapse_topic_MotorValues4f_t){0}, false, false);
	}
	shell_print(sh, "all motor tests stopped");

	return 0;
}

static int cmd_motor_spin(const struct shell *sh, size_t argc, char **argv)
{
	char *end = NULL;
	long index;
	float value;

	ARG_UNUSED(argc);

	if (!cubs2_motor_output_ready()) {
		shell_error(sh, "dshot not ready");
		return -ENODEV;
	}

	index = strtol(argv[1], &end, 10);
	if (*argv[1] == '\0' || *end != '\0' || index < 0 || index > 3) {
		shell_error(sh, "index must be 0..3");
		return -EINVAL;
	}

	end = NULL;
	value = strtof(argv[2], &end);
	if (*argv[2] == '\0' || *end != '\0' || value < 0.0f || value > 1.0f) {
		shell_error(sh, "value must be 0.0..1.0");
		return -EINVAL;
	}

	cubs2_motor_test_set((size_t)index, value);
	shell_print(sh, "motor %ld set to %0.3f", index, (double)value);

	return 0;
}

static int cmd_motor_raw(const struct shell *sh, size_t argc, char **argv)
{
	char *end = NULL;
	long index;
	long value;

	ARG_UNUSED(argc);

	if (!cubs2_motor_output_ready()) {
		shell_error(sh, "dshot not ready");
		return -ENODEV;
	}

	index = strtol(argv[1], &end, 10);
	if (*argv[1] == '\0' || *end != '\0' || index < 0 || index > 3) {
		shell_error(sh, "index must be 0..3");
		return -EINVAL;
	}

	end = NULL;
	value = strtol(argv[2], &end, 10);
	if (*argv[2] == '\0' || *end != '\0' || value < 0 || value > DSHOT_MAX) {
		shell_error(sh, "value must be 0 or 48..2047");
		return -EINVAL;
	}
	if (value != 0 && value < DSHOT_MIN) {
		shell_error(sh, "value must be 0 or 48..2047");
		return -EINVAL;
	}

	cubs2_motor_test_clear();
	cubs2_motor_raw_test_set((size_t)index, (uint16_t)value);
	shell_print(sh, "raw motor %ld set to %ld", index, value);

	return 0;
}

static int cmd_motor_raw_all(const struct shell *sh, size_t argc, char **argv)
{
	char *end = NULL;
	long value;

	ARG_UNUSED(argc);

	if (!cubs2_motor_output_ready()) {
		shell_error(sh, "dshot not ready");
		return -ENODEV;
	}

	value = strtol(argv[1], &end, 10);
	if (*argv[1] == '\0' || *end != '\0' || value < 0 || value > DSHOT_MAX) {
		shell_error(sh, "value must be 0 or 48..2047");
		return -EINVAL;
	}
	if (value != 0 && value < DSHOT_MIN) {
		shell_error(sh, "value must be 0 or 48..2047");
		return -EINVAL;
	}

	cubs2_motor_test_clear();
	cubs2_motor_raw_test_set_all((uint16_t)value);
	shell_print(sh, "all raw motors set to %ld", value);

	return 0;
}

SHELL_STATIC_SUBCMD_SET_CREATE(
	sub_motor,
	SHELL_CMD_ARG(spin, NULL, "spin one motor: motor spin <index:0..3> <value:0..1>",
		      cmd_motor_spin, 3, 0),
	SHELL_CMD_ARG(raw, NULL, "set one motor raw: motor raw <index:0..3> <value:0|48..2047>",
		      cmd_motor_raw, 3, 0),
	SHELL_CMD_ARG(raw_all, NULL, "set all motors raw: motor raw_all <value:0|48..2047>",
		      cmd_motor_raw_all, 2, 0),
	SHELL_CMD(stop, NULL, "stop all motor tests", cmd_motor_stop),
	SHELL_CMD(status, NULL, "show motor test state", cmd_motor_status),
	SHELL_SUBCMD_SET_END);
SHELL_CMD_REGISTER(motor, &sub_motor, "bench motor commands", NULL);
```

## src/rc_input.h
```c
/*
 * SPDX-License-Identifier: Apache-2.0
 */

#ifndef CUBS2_RC_INPUT_H_
#define CUBS2_RC_INPUT_H_

/* Native-SITL reports RC metadata through MSC events on the fake RC device. */
#define CUBS2_RC_INPUT_EVENT_LINK_QUALITY 1
#define CUBS2_RC_INPUT_EVENT_VALID 2

#endif /* CUBS2_RC_INPUT_H_ */
```

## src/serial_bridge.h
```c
#ifndef CUBS2_SERIAL_BRIDGE_H_
#define CUBS2_SERIAL_BRIDGE_H_

#include "topic_flatbuffer.h"

int cubs2_serial_bridge_init(void);
void cubs2_serial_bridge_send_rc(const synapse_topic_RcChannels16_t *rc);
bool cubs2_serial_bridge_get_mocap(cubs2_mocap_rigid_body_t *rb);

#endif
```
